# N570F064_v4_2 register map
File version: 1.0
Registers are 32-bit, read-write, reset 0x0 unless marked. A register's access mark holds for its fields unless they carry their own. Offsets are from the block's base; [hi:lo] are bit positions; {n}, {i} and the like mark numbered series.

## SPIM — SPIM Register Map
Base 0x50007000
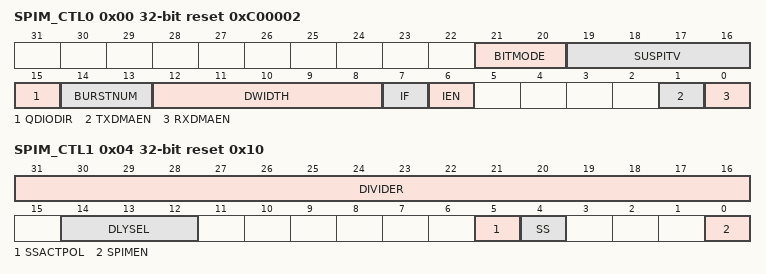
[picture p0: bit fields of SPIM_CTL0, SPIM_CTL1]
0x00 SPIM_CTL0 reset 0xC00002 — Control and Status Register 0
  [21:20] BITMODE — SPI Interface Bit Mode. Note. SPIM_MOSI is Data 0 pin for Quad Mode. SPIM_MISO is Data 1 pin for Quad Mode.
    0=Standard mode; 1=Dual mode; 2=Quad mode
  [19:16] SUSPITV — Suspend Interval
    0=2 HCLK clock cycles; 1=3 HCLK clock cycles; 14=16 HCLK clock cycles; 15=17 HCLK clock cycles
  [15] QDIODIR — SPI Interface Direction Select For Quad/Dual Mode
    0=Interface signals are input; 1=Interface signals are output
  [14:13] BURSTNUM — Transmit/Receive Burst Number. This field specifies how many transmit/receive transactions should be executed continuously in one transfer.
    0=Only one transmit/receive transaction will be executed in one transfer; 1=Two successive transmit/receive transactions will be executed in one transfer; 2=Three successive transmit/receive transactions will be executed in one transfer; 3=Four successive transmit/receive transactions will be executed in one transfer
  [12:8] DWIDTH — Transmit/Receive Bit Length. This field specifies how many bits are transmitted/received in one transmit/receive transaction. Note: Only 8-, 16-, 24-, and 32-bit are allowed. Other bit length will result in incorrect transfer.
    7=8 bits; 15=16 bits; 23=24 bits; 31=32 bits
  [7] IF — Interrupt Flag. Write Operation:
    0=No effect. The transfer has not finished yet; 1=Write 1 to clear. The transfer has done
  [6] IEN — Interrupt Enable Control
    0=SPIM Interrupt Disabled; 1=SPIM Interrupt Enabled
  [1] TXDMAEN — TX DMA Enable Control Bit. If set TXDMAEN to high, SPI interface will transfer the data to slave automatically. Note: Only support master mode. Note2: Before setting RXDMAEN, user must set PDMA register correctly first.
    0=DMA Disabled; 1=DMA Enable
  [0] RXDMAEN — RX DMA Enable Control Bit. If set RXDMAEN to high, SPI interface will receive the data from slave automatically. Note: Only support master mode. Note2: Before setting RXDMAEN, user must set PDMA register correctly first.
    0=DMA Disabled; 1=DMA Enable
0x04 SPIM_CTL1 reset 0x10 — Control Register 1
  [31:16] DIVIDER — Clock Divider Register. The value in this field is the frequency divider of the system clock to generate the serial clock on the output SPIM_CLK pin. The desired frequency is obtained according to the following equation: . Note: When set DIVIDER to zero, the frequency of SPIM_CLK will be equal to the frequency of SYS_CLK.
  [14:12] DLYSEL — RX Sample Clock Source Delay Chain Select
    0=Not Delay; 1=Select sample clock through 2 Delay Cell; 2=Select sample clock through 4 Delay Cell; 3=Select sample clock through 6 Delay Cell; 7=Select sample clock through 14 Delay Cell
  [5] SSACTPOL — Slave Select Active Level. It defines the active level of device/slave select signal (SPIM_SS).
    0=The SPIM_SS slave select signal is Active Low; 1=The SPIM_SS slave select signal is Active High
  [4] SS — Slave Select Active Enable Control. Note: This interface can only drive one device/slave at a given time. Therefore, the slave selects of the selected device must be set to its active level before starting any read or write transfer.
    0=SPIM_SS is in active level; 1=SPIM_SS is in inactive level
  [0] SPIMEN — Go and Busy Status. Write Operation: Note: All registers should be set before writing 1 to the SPIMEN bit. When a transfer is in progress, you should not write to any register of this peripheral.
    0=No effect. The transfer has done; 1=Start the transfer. This bit remains set during the transfer and is automatically cleared after transfer finished. The transfer has not finished yet
{0x10+4i} SPIM_RX{i} ro (i=0..3) — Data Receive Register {i}
  [31:0] RX — Data Receive Register. The Data Receive Registers hold the received data of the last executed transfer. Number of valid RX registers is specified in SPIM_CTL0[BURSTNUM]. If BURSTNUM > 0, received data are held in the most significant RX register first. Number of valid-bit is specified in SPIM_CTL0[DWIDTH]. If DWIDTH is 16, 24, or 32, received data are held in the least significant byte of RX register first. In a byte, received data are held in the most significant bit of RX register first.
{0x20+4i} SPIM_TX{i} (i=0..3) — Data Transmit Register {i}
  [31:0] TX — Data Transmit Register. The Data Transmit Registers hold the data to be transmitted in next transfer. Number of valid TX registers is specified in SPIM_CTL0[BURSTNUM]. If BURSTNUM > 0, data are transmitted in the most significant TX register first. Number of valid-bit is specified in SPIM_CTL0[DWIDTH]. If DWIDTH is 16, 24, or 32, data are transmitted in the least significant byte of TX register first. In a byte, data are transmitted in the most significant bit of TX register first.
